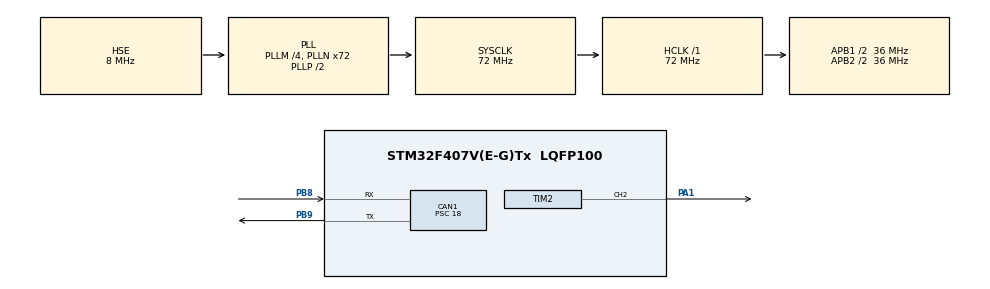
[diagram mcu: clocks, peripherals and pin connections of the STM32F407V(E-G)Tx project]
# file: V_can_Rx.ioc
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CAN1.BS1=CAN_BS1_2TQ
CAN1.CalculateBaudRate=500000
CAN1.CalculateTimeBit=2000
CAN1.CalculateTimeQuantum=500.0
CAN1.Mode=CAN_MODE_NORMAL
CAN1.Prescaler=18
CAN1.SJW=CAN_SJW_1TQ
Mcu.Family=STM32F4
Mcu.Name=STM32F407V(E-G)Tx
Mcu.Package=LQFP100
NVIC.CAN1_RX0_IRQn=true\:0\:0\:false\:false\:true\:true\:true\:true
NVIC.PriorityGroup=NVIC_PRIORITYGROUP_0
PA1.Signal=S_TIM2_CH2
PB8.Mode=CAN_Activate
PB8.Signal=CAN1_RX
PB9.Mode=CAN_Activate
PB9.Signal=CAN1_TX
PH0-OSC_IN.Mode=HSE-External-Oscillator
PH0-OSC_IN.Signal=RCC_OSC_IN
PH1-OSC_OUT.Mode=HSE-External-Oscillator
PH1-OSC_OUT.Signal=RCC_OSC_OUT
ProjectManager.HeapSize=0x200
ProjectManager.StackSize=0x400
ProjectManager.TargetToolchain=STM32CubeIDE
RCC.48MHZClocksFreq_Value=20571428.57142857
RCC.AHBFreq_Value=72000000
RCC.APB1CLKDivider=RCC_HCLK_DIV2
RCC.APB1Freq_Value=36000000
RCC.APB1TimFreq_Value=72000000
RCC.APB2CLKDivider=RCC_HCLK_DIV2
RCC.APB2Freq_Value=36000000
RCC.APB2TimFreq_Value=72000000
RCC.CortexFreq_Value=72000000
RCC.HCLKFreq_Value=72000000
RCC.HSE_VALUE=8000000
RCC.HSI_VALUE=16000000
RCC.LSE_VALUE=32768
RCC.PLLM=4
RCC.PLLN=72
RCC.PLLQ=7
RCC.PLLSourceVirtual=RCC_PLLSOURCE_HSE
RCC.SYSCLKFreq_VALUE=72000000
RCC.SYSCLKSource=RCC_SYSCLKSOURCE_PLLCLK
RCC.VCOOutputFreq_Value=144000000
SH.S_TIM2_CH2.0=TIM2_CH2,PWM Generation2 CH2
TIM2.Channel-PWM\ Generation2\ CH2=TIM_CHANNEL_2
TIM2.Period=10000-1
TIM2.Prescaler=360-1
VP_TIM2_VS_ClockSourceINT.Mode=Internal
board=STM32F407G-DISC1

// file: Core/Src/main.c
/* USER CODE BEGIN Header */
/**
  ******************************************************************************
  * @file           : main.c
  * @brief          : Main program body
  ******************************************************************************
  * @attention
  *
  * Copyright (c) 2024 STMicroelectronics.
  * All rights reserved.
  *
  * This software is licensed under terms that can be found in the LICENSE file
  * in the root directory of this software component.
  * If no LICENSE file comes with this software, it is provided AS-IS.
  *
  ******************************************************************************
  */
/* USER CODE END Header */
#include "main.h"

CAN_HandleTypeDef hcan1;

TIM_HandleTypeDef htim2;

/* USER CODE BEGIN PV */

int i;
uint16_t moisture = 0;

/* USER CODE END PV */

void SystemClock_Config(void);
static void MX_GPIO_Init(void);
static void MX_CAN1_Init(void);
static void MX_TIM2_Init(void);

/* USER CODE BEGIN 0 */
CAN_RxHeaderTypeDef RxHeader;
uint8_t RxData[8];
void Wiper_Operation(void);

void HAL_CAN_RxFifo0MsgPendingCallback(CAN_HandleTypeDef *hcan) {
	HAL_CAN_GetRxMessage(hcan, CAN_RX_FIFO0, &RxHeader, RxData);
	moisture  = RxData[0];
	moisture |= (RxData[1] | 0x0000) << 8;
	// process the message
}
/* USER CODE END 0 */

int main(void)
{

  /* MCU Configuration--------------------------------------------------------*/

  /* Reset of all peripherals, Initializes the Flash interface and the Systick. */
  HAL_Init();

  /* Configure the system clock */
  SystemClock_Config();

  /* Initialize all configured peripherals */
  MX_GPIO_Init();
  MX_CAN1_Init();
  MX_TIM2_Init();
  /* USER CODE BEGIN 2 */
  HAL_TIM_PWM_Start(&htim2,TIM_CHANNEL_2);
  HAL_CAN_Start(&hcan1);
  HAL_CAN_ActivateNotification(&hcan1, CAN_IT_RX_FIFO0_MSG_PENDING);

  // send first CAN message
  /*CAN_TxHeaderTypeDef TxHeader1;
  TxHeader1.DLC = 4;
  TxHeader1.RTR = CAN_RTR_DATA;
  TxHeader1.IDE = CAN_ID_STD;
  TxHeader1.StdId = 0x0A9;
  TxHeader1.ExtId = 0x0000;
  TxHeader1.TransmitGlobalTime = DISABLE;
  uint8_t TxData1[8] = "DESD";
  uint32_t TxMailBox1;
  if(HAL_CAN_AddTxMessage(&hcan1, &TxHeader1, TxData1, &TxMailBox1) != HAL_OK)
	  Error_Handler();
  */
  // send second CAN message
//  CAN_TxHeaderTypeDef TxHeader2;
//  TxHeader2.DLC = 7;
//  TxHeader2.RTR = CAN_RTR_DATA;
//  TxHeader2.IDE = CAN_ID_STD;
//  TxHeader2.StdId = 0x0AA;
//  TxHeader2.ExtId = 0x0000;
//  TxHeader2.TransmitGlobalTime = DISABLE;
//  uint8_t TxData2[8] = "SUNBEAM";
//  uint32_t TxMailBox2;

  // send third CAN message
  /*CAN_TxHeaderTypeDef TxHeader3;
  TxHeader3.DLC = 5;
  TxHeader3.RTR = CAN_RTR_DATA;
  TxHeader3.IDE = CAN_ID_STD;
  TxHeader3.StdId = 0x0AC;
  TxHeader3.ExtId = 0x0000;
  TxHeader3.TransmitGlobalTime = DISABLE;
  uint32_t TxMailBox3;
  uint8_t TxData3[8] = "C-DAC";
  if(HAL_CAN_AddTxMessage(&hcan1, &TxHeader3, TxData3, &TxMailBox3) != HAL_OK)
	  Error_Handler();
  /* USER CODE END 2 */

  /* Infinite loop */
  while (1)
  {

    /* USER CODE BEGIN 3 */

	  if(moisture < 2500)
	  {
		  Wiper_Operation();
	  }

  }
  /* USER CODE END 3 */
}

void SystemClock_Config(void)
{
  RCC_OscInitTypeDef RCC_OscInitStruct = {0};
  RCC_ClkInitTypeDef RCC_ClkInitStruct = {0};

  /** Configure the main internal regulator output voltage
  */
  __HAL_RCC_PWR_CLK_ENABLE();
  __HAL_PWR_VOLTAGESCALING_CONFIG(PWR_REGULATOR_VOLTAGE_SCALE1);

  /** Initializes the RCC Oscillators according to the specified parameters
  * in the RCC_OscInitTypeDef structure.
  */
  RCC_OscInitStruct.OscillatorType = RCC_OSCILLATORTYPE_HSE;
  RCC_OscInitStruct.HSEState = RCC_HSE_ON;
  RCC_OscInitStruct.PLL.PLLState = RCC_PLL_ON;
  RCC_OscInitStruct.PLL.PLLSource = RCC_PLLSOURCE_HSE;
  RCC_OscInitStruct.PLL.PLLM = 4;
  RCC_OscInitStruct.PLL.PLLN = 72;
  RCC_OscInitStruct.PLL.PLLP = RCC_PLLP_DIV2;
  RCC_OscInitStruct.PLL.PLLQ = 7;
  if (HAL_RCC_OscConfig(&RCC_OscInitStruct) != HAL_OK)
  {
    Error_Handler();
  }

  /** Initializes the CPU, AHB and APB buses clocks
  */
  RCC_ClkInitStruct.ClockType = RCC_CLOCKTYPE_HCLK|RCC_CLOCKTYPE_SYSCLK
                              |RCC_CLOCKTYPE_PCLK1|RCC_CLOCKTYPE_PCLK2;
  RCC_ClkInitStruct.SYSCLKSource = RCC_SYSCLKSOURCE_PLLCLK;
  RCC_ClkInitStruct.AHBCLKDivider = RCC_SYSCLK_DIV1;
  RCC_ClkInitStruct.APB1CLKDivider = RCC_HCLK_DIV2;
  RCC_ClkInitStruct.APB2CLKDivider = RCC_HCLK_DIV2;

  if (HAL_RCC_ClockConfig(&RCC_ClkInitStruct, FLASH_LATENCY_2) != HAL_OK)
  {
    Error_Handler();
  }
}

static void MX_CAN1_Init(void)
{

  hcan1.Instance = CAN1;
  hcan1.Init.Prescaler = 18;
  hcan1.Init.Mode = CAN_MODE_NORMAL;
  hcan1.Init.SyncJumpWidth = CAN_SJW_1TQ;
  hcan1.Init.TimeSeg1 = CAN_BS1_2TQ;
  hcan1.Init.TimeSeg2 = CAN_BS2_1TQ;
  hcan1.Init.TimeTriggeredMode = DISABLE;
  hcan1.Init.AutoBusOff = DISABLE;
  hcan1.Init.AutoWakeUp = DISABLE;
  hcan1.Init.AutoRetransmission = DISABLE;
  hcan1.Init.ReceiveFifoLocked = DISABLE;
  hcan1.Init.TransmitFifoPriority = DISABLE;
  if (HAL_CAN_Init(&hcan1) != HAL_OK)
  {
    Error_Handler();
  }
  /* USER CODE BEGIN CAN1_Init 2 */

  CAN_FilterTypeDef FilterConfig;
  FilterConfig.SlaveStartFilterBank = 9; // CAN1-0 to 8, CAN2-9 to 27
  FilterConfig.FilterActivation = CAN_FILTER_ENABLE;
  FilterConfig.FilterBank = 5; // Use any Filter from 0 to 8
  FilterConfig.FilterScale = CAN_FILTERSCALE_32BIT; // Use a 32-bit filter
  FilterConfig.FilterMode = CAN_FILTERMODE_IDMASK;
  FilterConfig.FilterMaskIdHigh = 0xFF00;
  FilterConfig.FilterMaskIdLow = 0x0000;
  FilterConfig.FilterIdHigh = 0x1500;
  FilterConfig.FilterIdLow = 0x0000;
  FilterConfig.FilterFIFOAssignment = CAN_RX_FIFO0;

  if(HAL_CAN_ConfigFilter(&hcan1, &FilterConfig) != HAL_OK)
	  Error_Handler();
  /* USER CODE END CAN1_Init 2 */

}

static void MX_TIM2_Init(void)
{

  TIM_ClockConfigTypeDef sClockSourceConfig = {0};
  TIM_MasterConfigTypeDef sMasterConfig = {0};
  TIM_OC_InitTypeDef sConfigOC = {0};

  htim2.Instance = TIM2;
  htim2.Init.Prescaler = 288-1;
  htim2.Init.CounterMode = TIM_COUNTERMODE_UP;
  htim2.Init.Period = 10000-1;
  htim2.Init.ClockDivision = TIM_CLOCKDIVISION_DIV1;
  htim2.Init.AutoReloadPreload = TIM_AUTORELOAD_PRELOAD_DISABLE;
  if (HAL_TIM_Base_Init(&htim2) != HAL_OK)
  {
    Error_Handler();
  }
  sClockSourceConfig.ClockSource = TIM_CLOCKSOURCE_INTERNAL;
  if (HAL_TIM_ConfigClockSource(&htim2, &sClockSourceConfig) != HAL_OK)
  {
    Error_Handler();
  }
  if (HAL_TIM_PWM_Init(&htim2) != HAL_OK)
  {
    Error_Handler();
  }
  sMasterConfig.MasterOutputTrigger = TIM_TRGO_RESET;
  sMasterConfig.MasterSlaveMode = TIM_MASTERSLAVEMODE_DISABLE;
  if (HAL_TIMEx_MasterConfigSynchronization(&htim2, &sMasterConfig) != HAL_OK)
  {
    Error_Handler();
  }
  sConfigOC.OCMode = TIM_OCMODE_PWM1;
  sConfigOC.Pulse = 0;
  sConfigOC.OCPolarity = TIM_OCPOLARITY_HIGH;
  sConfigOC.OCFastMode = TIM_OCFAST_DISABLE;
  if (HAL_TIM_PWM_ConfigChannel(&htim2, &sConfigOC, TIM_CHANNEL_2) != HAL_OK)
  {
    Error_Handler();
  }
  HAL_TIM_MspPostInit(&htim2);

}

static void MX_GPIO_Init(void)
{

  /* GPIO Ports Clock Enable */
  __HAL_RCC_GPIOH_CLK_ENABLE();
  __HAL_RCC_GPIOA_CLK_ENABLE();
  __HAL_RCC_GPIOB_CLK_ENABLE();

}

/* USER CODE BEGIN 4 */

void Wiper_Operation(void)
{

	for(i=0;i<600;i++)
	{
		__HAL_TIM_SET_COMPARE(&htim2,TIM_CHANNEL_2,i+1);
		HAL_Delay(2);
    }

	for(i=600;i>0;i--)
    {
		__HAL_TIM_SET_COMPARE(&htim2,TIM_CHANNEL_2,i-1);
		HAL_Delay(2);
	}
}

/* USER CODE END 4 */

void Error_Handler(void)
{
  /* USER CODE BEGIN Error_Handler_Debug */
  /* User can add his own implementation to report the HAL error return state */
  __disable_irq();
  while (1)
  {
	  // Blink RED Led ...
  }
  /* USER CODE END Error_Handler_Debug */
}
